# CLK1_FLAGMUX_CLK1 register map
Vendor: Texas Instruments
Peripheral module from a debugger description file (folder am572x).
Registers are 32-bit, read-only, no defined reset value unless marked. A register's access mark holds for its fields unless they carry their own. Offsets are as the file gives them; lines under a group give offsets from that group; [hi:lo] are bit positions; {n}, {i} and the like mark numbered series; 'fields as' and 'values as' point back to an identical list; <NAME> marks a mode.

## CLK1_FLAGMUX_CLK1
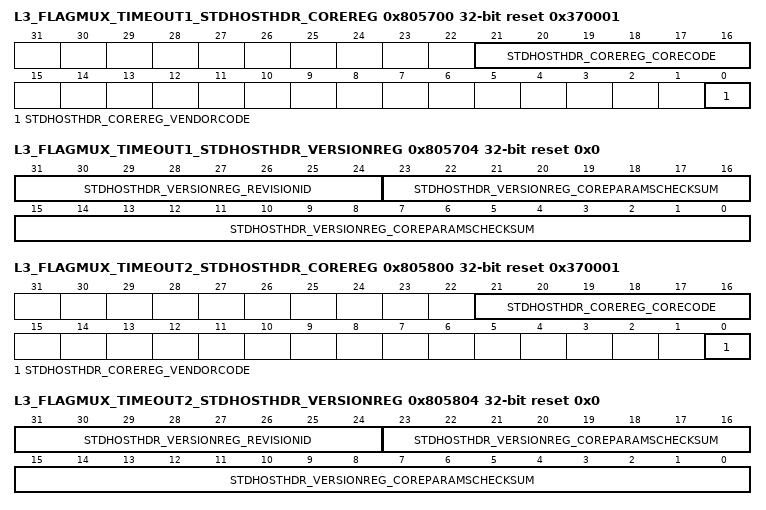
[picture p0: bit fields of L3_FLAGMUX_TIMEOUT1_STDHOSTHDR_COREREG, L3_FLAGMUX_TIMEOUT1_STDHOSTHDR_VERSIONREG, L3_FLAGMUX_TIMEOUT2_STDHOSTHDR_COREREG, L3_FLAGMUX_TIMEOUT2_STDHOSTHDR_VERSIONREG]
0x805700 L3_FLAGMUX_TIMEOUT1_STDHOSTHDR_COREREG reset 0x370001
  [21:16] STDHOSTHDR_COREREG_CORECODE — The Core Code field is a constantreporting a vendor-specific core generator code. Type: Constant. Reset value: 0x37.
  [0] STDHOSTHDR_COREREG_VENDORCODE — The Vendor Code field is a constantreporting the core generator vendor code. Type: Constant. Reset value: 0x1.
    1=ARTERIS; 0=UNDEFINED (Third-party vendor.)
0x805704 L3_FLAGMUX_TIMEOUT1_STDHOSTHDR_VERSIONREG reset 0x0 (reset mask 0xFF000000)
  [31:24] STDHOSTHDR_VERSIONREG_REVISIONID — The Revision Identifier field is a constantreporting the core generator revision number. Type: Constant. Reset value: 0x0.
  [23:0] STDHOSTHDR_VERSIONREG_COREPARAMSCHECKSUM — Reserved. Type: Reserved. Reset value: Reserved.
0x805708 L3_FLAGMUX_TIMEOUT1_MASK0 access per field reset 0x3FFFFFFF
  [29:0] MASK0 rw — mask flag inputs 0 Type: Control. Reset value: 0x0.
0x80570C L3_FLAGMUX_TIMEOUT1_REGERR0
  [24:0] REGERR0 — flag inputs 0 Type: Status. Reset value: X.
0x805800 L3_FLAGMUX_TIMEOUT2_STDHOSTHDR_COREREG reset 0x370001
  fields as L3_FLAGMUX_TIMEOUT1_STDHOSTHDR_COREREG
0x805804 L3_FLAGMUX_TIMEOUT2_STDHOSTHDR_VERSIONREG reset 0x0 (reset mask 0xFF000000)
  fields as L3_FLAGMUX_TIMEOUT1_STDHOSTHDR_VERSIONREG
0x805808 L3_FLAGMUX_TIMEOUT2_MASK0 access per field
  [20:0] MASK0 rw — mask flag inputs 0 Type: Control. Reset value: 0x0.
0x80580C L3_FLAGMUX_TIMEOUT2_REGERR0
  [20:0] REGERR0 — flag inputs 0 Type: Status. Reset value: X.
